# PIC32MZ1025W104132 device description
Architecture: MIPS; Family: PIC32MZW; Series: PIC32MZW
Registers are 32-bit, read-write, no defined reset value unless marked. A register's access mark holds for its fields unless they carry their own. Offsets are from the block's base; [hi:lo] are bit positions; {n}, {i} and the like mark numbered series.

## SQI
Instances: SQI 0x1f8e1000 in periph_indep_a
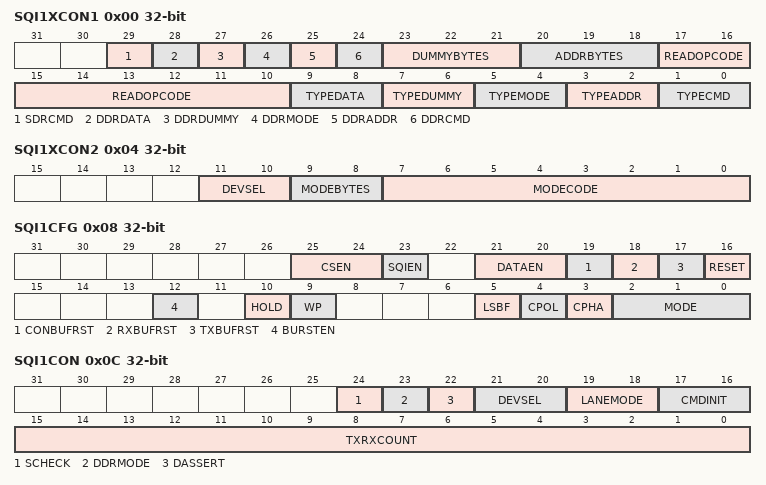
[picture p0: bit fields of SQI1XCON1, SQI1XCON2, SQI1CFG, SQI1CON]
0x00 SQI1XCON1 — SQI XIP Control Register 1
  [29] SDRCMD — SQI Command in SDR Mode bit
    0=SQI command is in SDR mode and SQI data is in DDR mode; 0=SQI command is in DDR mode and SQI data is in DDR mode
  [28] DDRDATA — SQI Data DDR Mode bit
    0=SQI data bytes are transferred in DDR mode; 0=SQI data bytes are transferred in SDR mode
  [27] DDRDUMMY — SQI Dummy DDR Mode bit
    0=SQI dummy bytes are transferred in DDR mode; 0=SQI dummy bytes are transferred in SDR mode
  [26] DDRMODE — SQI DDR Mode bit
    0=SQI mode bytes are transferred in DDR mode; 0=SQI mode bytes are transferred in SDR mode
  [25] DDRADDR — SQI Address Mode bit
    0=SQI address bytes are transferred in DDR mode; 0=SQI address bytes are transferred in SDR mode
  [24] DDRCMD — SQI DDR Command Mode bit
    0=SQI command bytes are transferred in DDR mode; 0=SQI command bytes are transferred in SDR mode
  [23:21] DUMMYBYTES — Transmit Dummy Bytes bits
    0=Transmit seven dummy bytes after the address bytes; 0=Transmit six dummy bytes after the address bytes; 0=Transmit five dummy bytes after the address bytes; 0=Transmit four dummy bytes after the address bytes; 0=Transmit three dummy bytes after the address bytes; 0=Transmit two dummy bytes after the address bytes; 0=Transmit one dummy bytes after the address bytes; 0=Transmit zero dummy bytes after the address bytes
  [20:18] ADDRBYTES
    0=Four address bytes; 0=Three address bytes; 0=Two address bytes; 0=One address bytes; 0=Zero address bytes
  [17:10] READOPCODE
  [9:8] TYPEDATA — The boot controller will receive the data in Single Lane, Dual Lane, or Quad Lane.
    0=Quad Lane mode data is enabled; 0=Dual Lane mode data is enabled; 0=Single Lane mode data is enabled
  [7:6] TYPEDUMMY — The boot controller will send the dummy in Single Lange, Dual Lane, or Quad Lane
    0=Quad Lane mode dummy is enabled; 0=Dual Lane mode dummy is enabled; 0=Single Lange mode dummy is enabled
  [5:4] TYPEMODE — The boot controller will send the mode in Single Lane, Dual Lane, or Quad Lane.
    0=Quad Lane mode is enabled; 0=Dual Lane mode is enabled; 0=Single Lane mode is enabled
  [3:2] TYPEADDR — The boot controller will send the address in Single Lane, Dual Lane, or Quad Lane.
    0=Quad Lane mode address is enabled; 0=Dual Lane mode address is enabled; 0=Single Lane mode address is enabled
  [1:0] TYPECMD — The boot controller will send the command in Single Lane, Dual Lane, or Quad Lane.
    2=Quad Lane mode command is enabled; 1=Dual Lane mode command is enabled; 0=Single Lane mode command is enabled
0x04 SQI1XCON2 — SQI XIP Control Register 2
  [11:10] DEVSEL — Device Select bits
    0=Device 1 is selected; 0=Device 0 is selected
  [9:8] MODEBYTES — Mode Byte Cycle Enable bits
    0=Three cycles; 0=Two cycles; 0=One cycle; 0=Zero cycles
  [7:0] MODECODE
0x08 SQI1CFG — SQI Configuration Register
  [25:24] CSEN — Chip Select Output Enable bits
    0=Chip Select 0 and Chip Select 1 are used; 0=Chip Select 1 is used (Chip Select 0 is not used); 0=Chip Select 0 is used (Chip Select 1 is not used); 0=Chip Select 0 and Chip Select 1 are not used
  [23] SQIEN — SQI Enable bit
    0=SQI module is enabled; 0=SQI module is disabled
  [21:20] DATAEN — Data Output Enable bits
    0=SQID3-SQID0 outputs are enabled; 0=SQID1 and SQID0 data outputs are enabled; 0=SQID0 data output is enabled
  [19] CONBUFRST — Control Buffer Reset bit
    0=A reset pulse is generated, clearing the control buffer; 0=A reset pulse is not generated
  [18] RXBUFRST — Receive Buffer Reset bit
    0=A reset pulse is generated clearing the receive buffer; 0=A reset pulse is not generated
  [17] TXBUFRST — Transmit Buffer Reset bit
    0=A reset pulse is generated clearing the transmit buffer; 0=A reset pulse is not generated
  [16] RESET — Software Reset Select bit
    0=A reset pulse is generated; 0=A reset pulse is not generated
  [12] BURSTEN — Burst Configuration bit
    0=Burst is enabled; 0=Burst is not enabled
  [10] HOLD
  [9] WP
  [5] LSBF — Data Format Select bit
    0=LSB is send or received first; 0=MSB is sent or received first
  [4] CPOL — Clock Polarity Select bit
    0=Active-low SQICLK (SQICLK high is the Idle state); 0=Active-high SQICLK (SQICLK low is the Idle state)
  [3] CPHA — Clock Phase Select bit
    0=SQICLK starts toggling at the start of the first data bit; 0=SQICLK starts toggling at the middle of the first data bit
  [2:0] MODE — Mode Select bits
    3=XIP mode is selected (when this mode is entered, the module behaves as if executing in place (XIP),but uses the register data to control timing); 2=DMA mode is selected; 1=CPU mode is selected (the module is controlled by the CPU in PIO mode. This mode is entered whenleaving Boot or XIP mode)
0x0C SQI1CON — SQI Control Register
  [24] SCHECK — Flash Status Check bit
    0=Check the status of the Flash; 0=Do not check the status of the Flash
  [23] DDRMODE — Double Data Rate Mode bit
    0=Set the SQI transfers to DDR mode; 0=Set the SQI transfers to SDR mode
  [22] DASSERT — Chip Select Assert bit
    0=Chip Select is deasserted after transmission or reception of the specified number of bytes; 0=Chip Select is not deasserted after transmission or reception of the specified number of bytes
  [21:20] DEVSEL — SQI Device Select bits
    0=Select Device 1; 0=Select Device 0
  [19:18] LANEMODE
  [17:16] CMDINIT
  [15:0] TXRXCOUNT
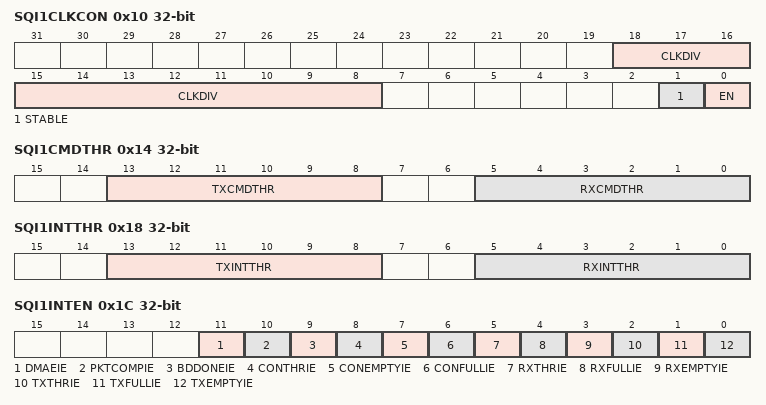
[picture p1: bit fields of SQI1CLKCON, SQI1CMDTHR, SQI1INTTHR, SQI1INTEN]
0x10 SQI1CLKCON — SQI Clock Control Register
  [18:8] CLKDIV — SQI Clock Tsqi Frequency Select bits
    2=Base Clock Tbc is divided by 2048; 1=Base Clock Tbc is divided by 1024; 0=Base Clock Tbc is divided by 512; 0=Base Clock Tbc is divided by 256; 0=Base Clock Tbc is divided by 128; 0=Base Clock Tbc is divided by 64; 0=Base Clock Tbc is divided by 32; 0=Base Clock Tbc is divided by 16; 0=Base Clock Tbc is divided by 8; 0=Base clock Tbc is divided by 4; 0=Base clock Tbc is divided by 2
  [1] STABLE — Tsqi Clock Stable Select bit
    0=Tsqi clock is stable; 0=Tsqi clock is not stable
  [0] EN — Tsqi Clock Enable Select bit
    1=Enable the SQI clock (Tsqi); 0=Disable the SQI clock (Tsqi)
0x14 SQI1CMDTHR — SQI Command Threshold Register
  [13:8] TXCMDTHR, [5:0] RXCMDTHR
0x18 SQI1INTTHR — SQI Interrupt Threshold Register
  [13:8] TXINTTHR, [5:0] RXINTTHR
0x1C SQI1INTEN — SQI Interrupt Enable Register
  [11] DMAEIE — DMA Bus Error Interrupt Enable bit
    0=Interrupt is enabled; 0=Interrupt is disabled
  [10] PKTCOMPIE — DMA Buffer Descriptor Packet Complete Interrupt Enable bit
    0=Interrupt is enabled; 0=Interrupt is disabled
  [9] BDDONEIE — DMA Buffer Descriptor Done Interrupt Enable bit
    0=Interrupt is enabled; 0=Interrupt is disabled
  [8] CONTHRIE — Control Buffer Threshold Interrupt Enable bit
    0=Interrupt is enabled; 0=Interrupt is disabled
  [7] CONEMPTYIE — Control Buffer Empty Interrupt Enabled bit
    0=Interrupt is enabled; 0=Interrupt is disabled
  [6] CONFULLIE — Control Buffer Full Interrupt Enable bit
    0=Interrupt is enabled; 0=Interrupt is disabled
  [5] RXTHRIE — Receive Buffer Threshold Interrupt Enable bit
    0=Interrupt is enabled; 0=Interrupt is disabled
  [4] RXFULLIE — Receive Buffer Full Interrupt Enable bit
    0=Interrupt is enabled; 0=Interrupt is disabled
  [3] RXEMPTYIE — Receive Buffer Empty Interrupt Enabled bit
    0=Interrupt is enabled; 0=Interrupt is disabled
  [2] TXTHRIE — Transmit Buffer Threshold Interrupt Enable bit
    0=Interrupt is enabled; 0=Interrupt is disabled
  [1] TXFULLIE — Transmit Buffer Full Interrupt Enable bit
    0=Interrupt is enabled; 0=Interrupt is disabled
  [0] TXEMPTYIE — Transmit Buffer Empty Interrupt Enable bit
    1=Interrupt is enabled; 0=Interrupt is disabled
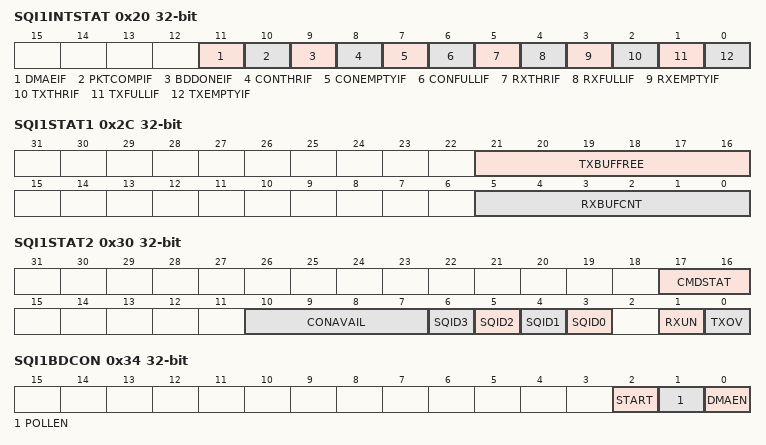
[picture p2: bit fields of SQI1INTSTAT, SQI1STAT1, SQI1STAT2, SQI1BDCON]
0x20 SQI1INTSTAT
  [11] DMAEIF — DMA Bus Error Interrupt Flag bit
    0=DMA bus error has occurred; 0=DMA bus error has not occurred
  [10] PKTCOMPIF — DMA Buffer Descriptor Processor Packet Complete Interrupt Status bit
    0=DMA BD packet is complete; 0=DMA BD packet is in progress
  [9] BDDONEIF — DMA Buffer Descriptor Done Interrupt Status bit
    0=DMA BD process is done; 0=DMA BD process is in progress
  [8] CONTHRIF — Control Buffer Threshold Interrupt Status bit
    0=The control buffer has THRES or more words of space available; 0=The control buffer has less than THRES words of space available
  [7] CONEMPTYIF — Control Buffer Empty Interrupt Status bit
    0=Control buffer is empty; 0=Control buffer is not empty
  [6] CONFULLIF — Control Buffer Full Interrupt Status bit
    0=Control buffer is full; 0=Control buffer is not full
  [5] RXTHRIF — Receive Buffer Threshold Interrupt Status bit
    0=Receive buffer has RXINTTHR or more words of space available; 0=Receive buffer has less than RXINTTHR words of space available
  [4] RXFULLIF — Receive Buffer Full Interrupt Status bit
    0=Receive buffer is full; 0=Receive buffer is not full
  [3] RXEMPTYIF — Receive Buffer Empty Interrupt Status bit
    0=Receive buffer is empty; 0=Receive buffer is not empty
  [2] TXTHRIF — Transmit Buffer Threshold Interrupt Status bit
    0=Transmit buffer has more than TXINTTHR words of space available; 0=Transmit buffer has less than TXINTTHR words of space available
  [1] TXFULLIF — Transmit Buffer Full Interrupt Status bit
    0=The transmit buffer is full; 0=The transmit buffer is not full
  [0] TXEMPTYIF — Transmit Buffer Empty Interrupt Status bit
    1=The transmit buffer is empty; 0=The transmit buffer has content
0x24 SQI1TXDATA — SQI Transmit Data Buffer Register
  [31:0] TXDATA
0x28 SQI1RXDATA ro — SQI Receive Data Buffer Register
  [31:0] RXDATA
0x2C SQI1STAT1 ro — SQI Status Register 1
  [21:16] TXBUFFREE, [5:0] RXBUFCNT
0x30 SQI1STAT2 ro — SQI Status Register 2
  [17:16] CMDSTAT — Current Command Status bits
    0=Receive; 0=Transmit; 0=Idle
  [10:7] CONAVAIL — Control IFO Space Available bits
    0=32 bytes are available; 0=31 bytes are available; 0=1 byte is available; 0=No bytes are available
  [n+3] SQID{n} (n=0..3) — SQID{n} Status bit
    0=Data is present on SQID{n}; 0=Data is not present on SQID{n}
  [1] RXUN — Receive Buffer Underflow Status bit
    0=Receive Buffer Underflow has occurred; 0=Receive Buffer Underflow has not occurred
  [0] TXOV — Transmit Buffer Overflow Status bit
    1=Transmit Buffer overflow has occurred; 0=Transmit Buffer overflow has not occurred
0x34 SQI1BDCON — SQI Buffer Descriptor Control Register
  [2] START — Buffer Descriptor Processor Start bit
    0=Start the buffer descriptor processor; 0=Disable the buffer descriptor processor
  [1] POLLEN — Buffer Descriptor Poll Enable bit
    0=BDP poll enabled; 0=BDP poll is not enabled
  [0] DMAEN — DMA Enable bit
    1=DMA is enabled; 0=DMA is disabled
0x38 SQI1BDCURADD ro — SQI Buffer Descriptor Current Address Register
  [31:0] BDCURRADDR
0x40 SQI1BDBASEADD — SQI Buffer Descriptor Base Address Register
  [31:0] BDADDR
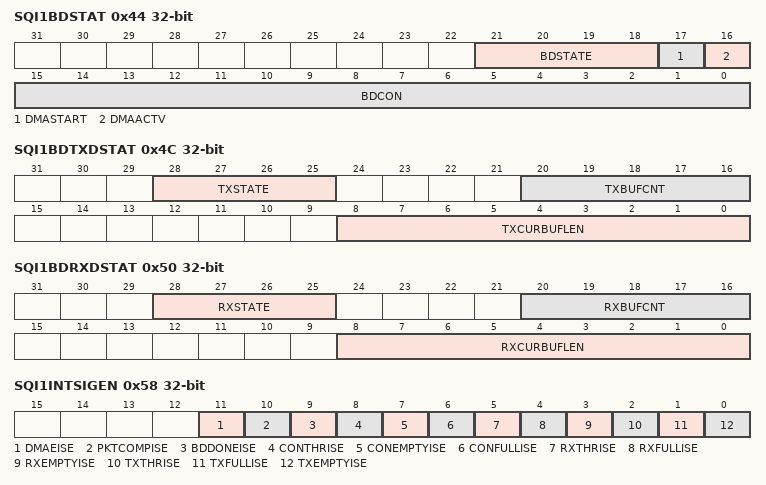
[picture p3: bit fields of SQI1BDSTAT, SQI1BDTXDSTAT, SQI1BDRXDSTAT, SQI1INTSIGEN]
0x44 SQI1BDSTAT ro — SQI Buffer Descriptor Status Register
  [21:18] BDSTATE — DMA Buffer Descriptor Processor State Status bits
    0=Fetched buffer descriptor is disabled; 0=Descriptor is done; 0=Data phase; 0=Buffer descriptor is loading; 0=Descriptor fetch request is pending; 0=Idle
  [17] DMASTART — DMA Buffer Descriptor Processor Start Status bit
    0=DMA has started; 0=DMA has not started
  [16] DMAACTV — DMA Buffer Descriptor Processor Active Status bit
    0=Buffer Descriptor Processor is active; 0=Buffer Descriptor Processor is idle
  [15:0] BDCON
0x48 SQI1BDPOLLCON — SQI Buffer Descriptor Poll Control Register
  [15:0] POLLCON
0x4C SQI1BDTXDSTAT ro — SQI Buffer Descriptor DMA Transmit Status Register
  [28:25] TXSTATE, [20:16] TXBUFCNT, [8:0] TXCURBUFLEN
0x50 SQI1BDRXDSTAT ro — SQI Buffer Descriptor DMA Receive Status Register
  [28:25] RXSTATE, [20:16] RXBUFCNT, [8:0] RXCURBUFLEN
0x54 SQI1THR — SQI Threshold Control Register
  [3:0] THRES
0x58 SQI1INTSIGEN — SQI Interrupt Signal Enable Register
  [11] DMAEISE — DMA Bus Error Interrupt Signal Enable bit
    0=Interrupt signal is enabled; 0=Interrupt signal is disabled
  [10] PKTCOMPISE — DMA Buffer Descriptor Packet Complete Interrupt Signal Enable bit
    0=Interrupt is enabled; 0=Interrupt is disabled
  [9] BDDONEISE — DMA Buffer Descriptor Done Interrupt Signal Enable bit
    0=Interrupt is enabled; 0=Interrupt is disabled
  [8] CONTHRISE — Control Buffer Threshold Interrupt Signal Enable bit
    0=Interrupt is enabled; 0=Interrupt is disabled
  [7] CONEMPTYISE — Control Buffer Empty Interrupt Signal Enable bit
    0=Interrupt is enabled; 0=Interrupt is disabled
  [6] CONFULLISE — Control Buffer Full Interrupt Signal Enable bit
    0=Interrupt is enabled; 0=Interrupt is disabled
  [5] RXTHRISE — Receive Buffer Threshold Interrupt Signal Enable bit
    0=Interrupt is enabled; 0=Interrupt is disabled
  [4] RXFULLISE — Receive Buffer Full Interrupt Signal Enable bit
    0=Interrupt is enabled; 0=Interrupt is disabled
  [3] RXEMPTYISE — Receive Buffer Empty Interrupt Signal Enable bit
    0=Interrupt is enabled; 0=Interrupt is disabled
  [2] TXTHRISE — Transmit Buffer Threshold Interrupt Signal Enable bit
    0=Interrupt is enabled; 0=Interrupt is disabled
  [1] TXFULLISE — Transmit Buffer Full Interrupt Signal Enable bit
    0=Interrupt is enabled; 0=Interrupt is disabled
  [0] TXEMPTYISE — Transmit Buffer Empty Interrupt Signal Enable bit
    1=Interrupt is enabled; 0=Interrupt is disabled
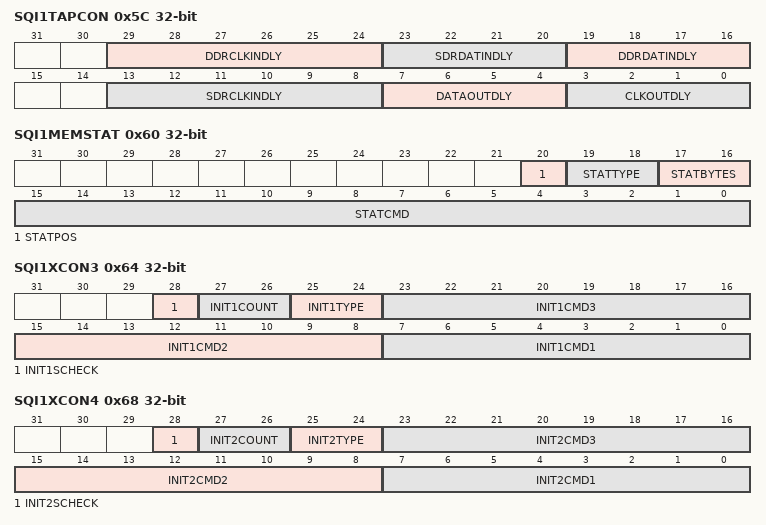
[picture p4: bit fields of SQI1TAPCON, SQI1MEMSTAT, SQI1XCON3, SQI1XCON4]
0x5C SQI1TAPCON — SQI Tap Control Register
  [29:24] DDRCLKINDLY
  [23:20] SDRDATINDLY
  [19:16] DDRDATINDLY
  [13:8] SDRCLKINDLY — SQI Clock Input Delay bits
    0=64 taps added on clock input; 0=63 taps added on clock input; 0=2 taps added on clock input; 0=1 tap added on clock input
  [7:4] DATAOUTDLY — SQI Data Output Delay bits
    0=16 taps added on clock output; 0=15 taps added on clock output; 0=2 taps added on clock output; 0=1 tap added on clock output
  [3:0] CLKOUTDLY — SQI Clock Output Delay bits
    15=16 taps added on clock output; 14=15 taps added on clock output; 1=2 taps added on clock output; 0=1 tap added on clock output
0x60 SQI1MEMSTAT — SQI Memory Status Register
  [20] STATPOS — Statis Bit Position in Flash bit
    0=BUSY bit position is bit 7 in status register; 0=BUSY bit position is bit 0 in status register
  [19:18] STATTYPE — Status Command/Read Lane Mode bits
    0=Status command and read are executed in Quad Lane mode; 0=Status command and read are executed in Dual Lane mode; 0=Status command and read are executed in Single Lane mode
  [17:16] STATBYTES — Number of Status Bytes bits
    0=Status command/read is 2 bytes long; 0=Status command/read is 1 byte long
  [15:0] STATCMD
0x64 SQI1XCON3 — SQI XIP Control Register 3
  [28] INIT1SCHECK — Flash Initialization 1 Command Status Check bit
    0=Check the status after executing the INIT1 command; 0=Do not check the status
  [27:26] INIT1COUNT — Flash Initialization 1 Command Count bits
    0=INIT1CMD3, INIT1CMD2, and INIT1CMD3 are sent; 0=INIT1CMD1 and INIT1CMD2 are sent, but INIT1CMD3 is still pending; 0=INIT1CMD1 is sent, but INIT1CMD2 and INIT1CMD3 are still pending; 0=No commands are sent
  [25:24] INIT1TYPE — Flash Initialization 1 Command Type bits
    0=INIT1 commands are sent in Quad Lane mode; 0=INIT1 commands are sent in Dual Lane mode; 0=INIT1 commadns are sent in Single Lane mode
  [23:16] INIT1CMD3
  [15:8] INIT1CMD2
  [7:0] INIT1CMD1
0x68 SQI1XCON4 — SQI XIP Control Register 4
  [28] INIT2SCHECK — Flash Initialization 2 Command Status Check bit
    0=Check the status after executing the INIT2 command; 0=Do not check the status
  [27:26] INIT2COUNT — Flash Initialization 2 Command Count bits
    0=INIT2CMD1, INIT2CMD2, and INIT2CMD3 are sent; 0=INIT2CMD1 and INIT2CMD2 are sent, but INIT2CMD3 is still pending; 0=INIT2CMD1 is sent, but INIT2CMD2 and INIT2CMD3 are still pending; 0=No commands are sent
  [25:24] INIT2TYPE — Flash Initialization 2 Command Type bits
    0=INIT2 commands are sent in Quad Lane mode; 0=INIT2 commands are sent in Dual Lane mode; 0=INIT2 commands are sent in Single Lane mode
  [23:16] INIT2CMD3
  [15:8] INIT2CMD2
  [7:0] INIT2CMD1
